VERSION ""

NS_ :

BS_:

BU_:

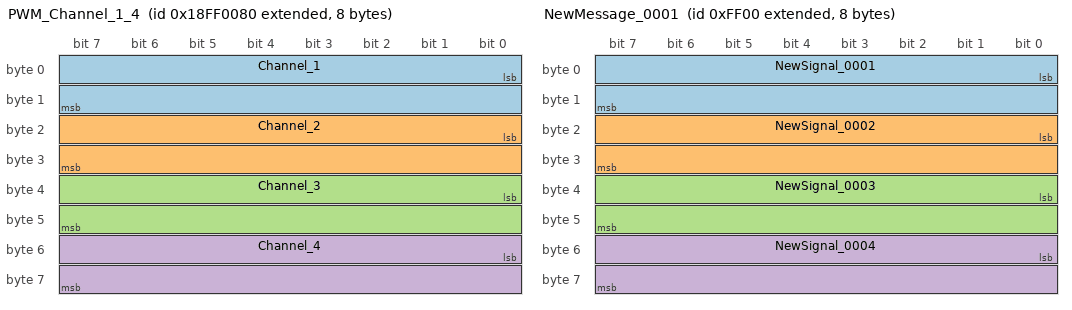
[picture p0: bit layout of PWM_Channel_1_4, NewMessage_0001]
BO_ 2566848640 PWM_Channel_1_4: 8 Vector__XXX
 SG_ Channel_1 : 0|16@1+ (1,-1426) [0|64255] "" Vector__XXX
 SG_ Channel_2 : 16|16@1+ (1,-1426) [0|0] "" Vector__XXX
 SG_ Channel_3 : 32|16@1+ (1,-1426) [0|0] "" Vector__XXX
 SG_ Channel_4 : 48|16@1+ (1,-1426) [0|0] "" Vector__XXX

BO_ 2147548928 NewMessage_0001: 8 Vector__XXX
 SG_ NewSignal_0001 : 0|16@1+ (1,0) [0|0] "" Vector__XXX
 SG_ NewSignal_0002 : 16|16@1+ (1,0) [0|0] "" Vector__XXX
 SG_ NewSignal_0003 : 32|16@1+ (1,0) [0|0] "" Vector__XXX
 SG_ NewSignal_0004 : 48|16@1+ (1,0) [0|0] "" Vector__XXX
